# STM32F303C6T6 register map
File version: 1.0
Registers are 32-bit, access not given, reset 0x0 unless marked. A register's access mark holds for its fields unless they carry their own. Offsets are from the block's base; [hi:lo] are bit positions; {n}, {i} and the like mark numbered series; 'fields as' and 'values as' point back to an identical list.

## FLASH
Base 0x40022000
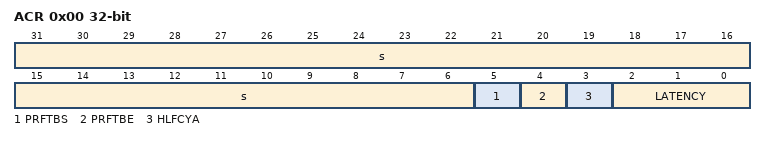
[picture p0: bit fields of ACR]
0x00 ACR
  [31:6] s, [5] PRFTBS, [4] PRFTBE, [3] HLFCYA, [2:0] LATENCY
0x04 KEYR
  [31:0] FKEYR
0x08 OPTKEYR
0x0C SR
  [5] EOP, [4] WRPRTERR, [2] PGERR, [31:1] s, [0] BSY
0x10 CR
  [13] OBL_LAUNCH, [12] EOPIE, [10] ERRIE, [9] OPTWRE, [7] LOCK, [6] STRT, [5] OPTER, [4] OPTPG, [31:3] s, [2] MER, [1] PER, [0] PG
0x14 AR
  [31:0] FAR
0x1C OBR
  [31:24] Data1, [23:16] Data0, [14] SRAM_PE, [13] VDDA_MONITOR, [12] nBOOT1, [10] nRST_STDBY, [9] nRST_STOP, [8] WDG_SW, [15:3] s, [2:1] RDPRT, [0] OPTERR
0x20 WRPR
  [31:0] WRP

## CRC
Base 0x40023000
0x00 DR
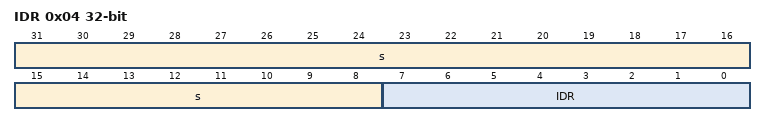
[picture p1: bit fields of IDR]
0x04 IDR
  [31:8] s, [7:0] IDR
0x08 CR
  [7] REV_OUT, [6:5] REV_IN, [4:3] POLYSIZE, [31:1] s, [0] RESET
0x10 INIT
  [31:0] CRC_INIT
0x14 POL
  [31:0] Polynomialcoefficients

## TSC
Base 0x40024000
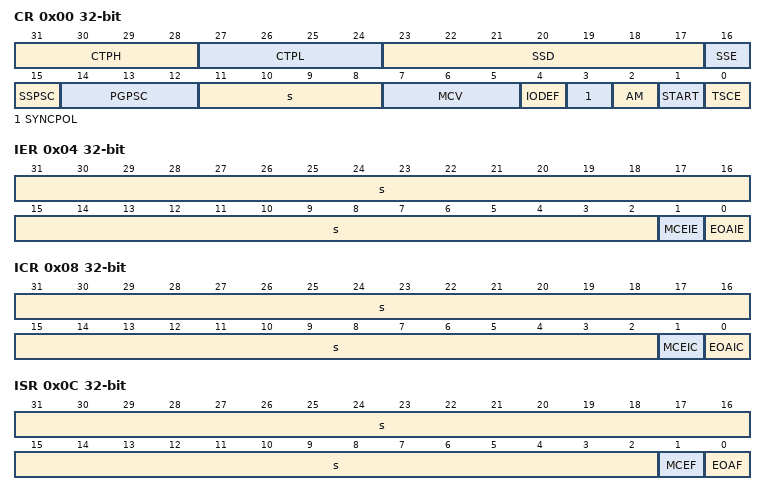
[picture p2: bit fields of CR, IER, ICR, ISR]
0x00 CR
  [31:28] CTPH, [27:24] CTPL, [23:17] SSD, [16] SSE, [15] SSPSC, [14:12] PGPSC, [11:8] s, [7:5] MCV, [4] IODEF, [3] SYNCPOL, [2] AM, [1] START, [0] TSCE
0x04 IER
  [31:2] s, [1] MCEIE, [0] EOAIE
0x08 ICR
  [31:2] s, [1] MCEIC, [0] EOAIC
0x0C ISR
  [31:2] s, [1] MCEF, [0] EOAF
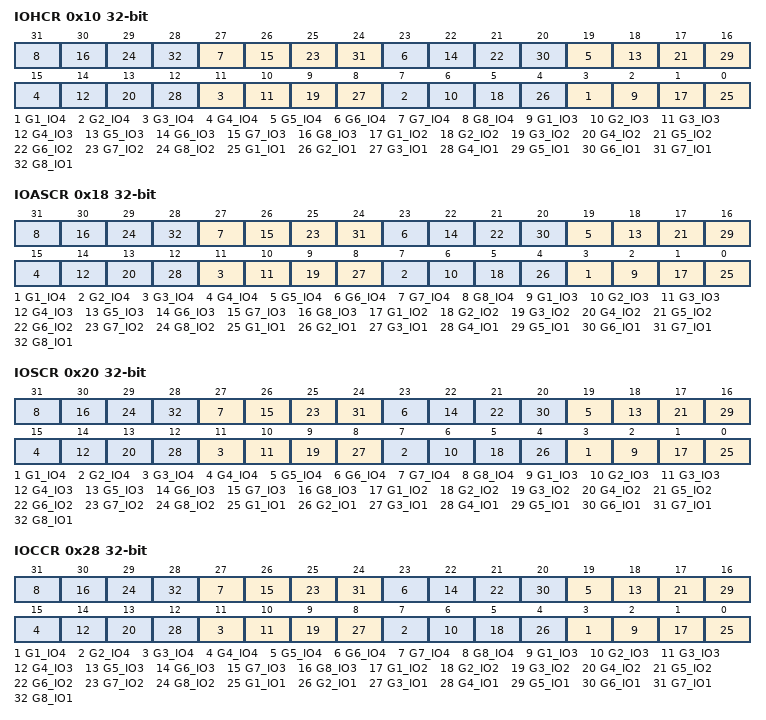
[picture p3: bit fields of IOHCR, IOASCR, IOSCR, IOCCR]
0x10 IOHCR
  [4n-1] G{n}_IO4 (n=1..8), [4n-2] G{n}_IO3 (n=1..8), [4n-3] G{n}_IO2 (n=1..8), [4n-4] G{n}_IO1 (n=1..8)
0x18 IOASCR
  fields as IOHCR
0x20 IOSCR
  fields as IOHCR
0x28 IOCCR
  fields as IOHCR
0x30 IOGCSR
  [n+15] G{n}S (n=1..8), [31:8] s, [n-1] G{n}E (n=1..8)
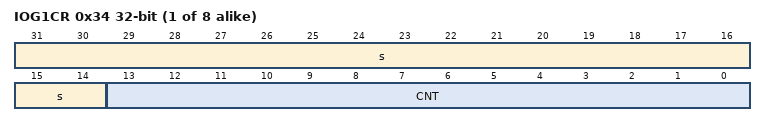
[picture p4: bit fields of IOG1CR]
{0x30+4i} IOG{i}CR (i=1..8)
  [31:14] s, [13:0] CNT

## GPIOA
Base 0x48000000
Same registers: GPIOB 0x48000400, GPIOC 0x48000800, GPIOD 0x48000C00, GPIOF 0x48001400
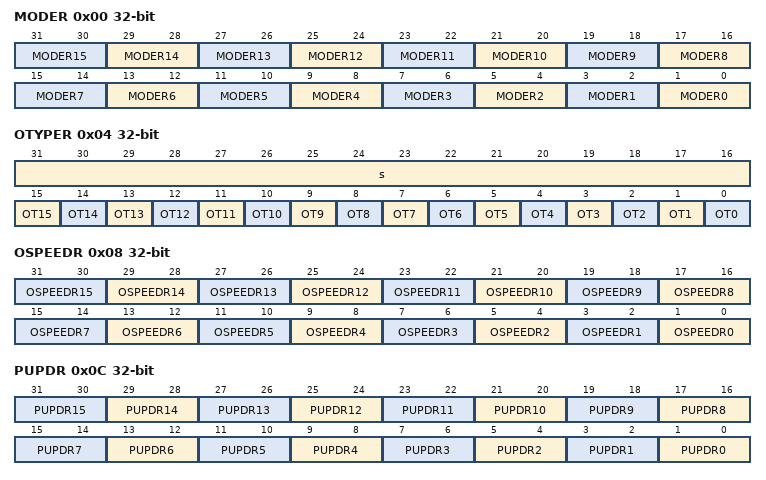
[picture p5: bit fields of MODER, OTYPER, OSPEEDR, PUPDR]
0x00 MODER
  [2n+1:2n] MODER{n} (n=0..15)
0x04 OTYPER
  [31:16] s, [n] OT{n} (n=0..15)
0x08 OSPEEDR
  [2n+1:2n] OSPEEDR{n} (n=0..15)
0x0C PUPDR
  [2n+1:2n] PUPDR{n} (n=0..15)
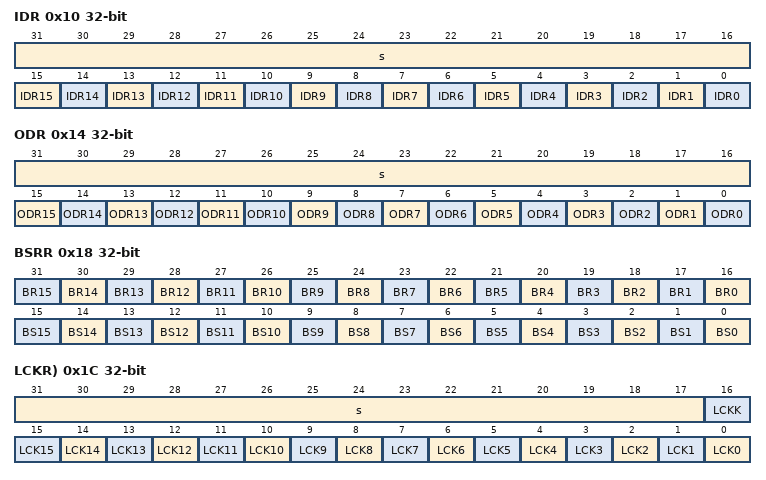
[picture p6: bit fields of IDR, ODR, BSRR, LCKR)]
0x10 IDR
  [31:16] s, [n] IDR{n} (n=0..15)
0x14 ODR
  [31:16] s, [n] ODR{n} (n=0..15)
0x18 BSRR
  [n+16] BR{n} (n=0..15), [n] BS{n} (n=0..15)
0x1C LCKR)
  [31:17] s, [16] LCKK, [n] LCK{n} (n=0..15)
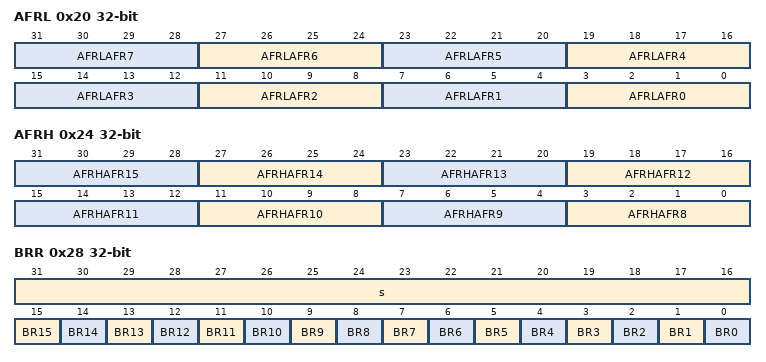
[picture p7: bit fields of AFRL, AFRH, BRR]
0x20 AFRL
  [4n+3:4n] AFRLAFR{n} (n=0..7)
0x24 AFRH
  [4n-29:4n-32] AFRHAFR{n} (n=8..15)
0x28 BRR
  [31:16] s, [n] BR{n} (n=0..15)

## ADC1
Base 0x50000000
Same registers: ADC2 0x50000100
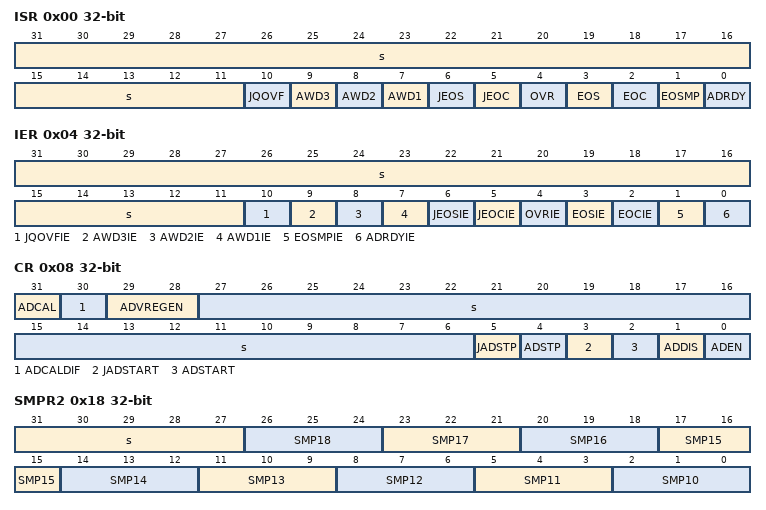
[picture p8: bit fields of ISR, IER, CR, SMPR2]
0x00 ISR
  [31:11] s, [10] JQOVF, [9] AWD3, [8] AWD2, [7] AWD1, [6] JEOS, [5] JEOC, [4] OVR, [3] EOS, [2] EOC, [1] EOSMP, [0] ADRDY
0x04 IER
  [31:11] s, [10] JQOVFIE, [9] AWD3IE, [8] AWD2IE, [7] AWD1IE, [6] JEOSIE, [5] JEOCIE, [4] OVRIE, [3] EOSIE, [2] EOCIE, [1] EOSMPIE, [0] ADRDYIE
0x08 CR
  [31] ADCAL, [30] ADCALDIF, [29:28] ADVREGEN, [27:6] s, [5] JADSTP, [4] ADSTP, [3] JADSTART, [2] ADSTART, [1] ADDIS, [0] ADEN
0x0C CFGR
  [30:26] AWD1CH, [25] JAUTO, [24] JAWD1EN, [23] AWD1EN, [22] AWD1SGL, [21] JQM, [20] JDISCEN, [19:17] DISCNUM, [16] DISCEN, [14] AUTDLY, [13] CONT, [12] OVRMOD, [11:10] EXTEN, [9:6] EXTSEL, [5] ALIGN, [4:3] RES, [31:2] s, [1] DMACFG, [0] DMAEN
0x14 SMPR1
  [3n+2:3n] SMP{n} (n=1..9), [31:0] s
0x18 SMPR2
  [31:27] s, [3n-28:3n-30] SMP{n} (n=10..18)
0x20 TR1
  [27:16] HT1, [31:12] s, [11:0] LT1
0x24 TR2
  [23:16] HT2, [31:8] s, [7:0] LT2
0x28 TR3
  [23:16] HT3, [31:8] s, [7:0] LT3
0x30 SQR1
  [6n+4:6n] SQ{n} (n=1..4), [31:4] s, [3:0] L
0x34 SQR2
  [6n-26:6n-30] SQ{n} (n=5..9), [31:5] s
0x38 SQR3
  [6n-56:6n-60] SQ{n} (n=10..14), [31:5] s
0x3C SQR4
  [10:6] SQ16, [31:5] s, [4:0] SQ15
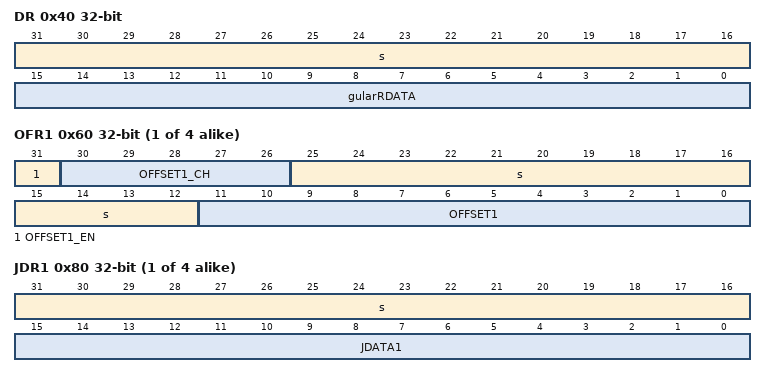
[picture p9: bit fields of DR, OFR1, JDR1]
0x40 DR
  [31:16] s, [15:0] gularRDATA
0x4C JSQR
  [6n+6:6n+2] JSQ{n} (n=1..4), [31:13] s, [7:6] JEXTEN, [5:2] JEXTSEL, [1:0] JL
{0x5C+4i} OFR{i} (i=1..4)
  [31] OFFSET{i}_EN, [30:26] OFFSET{i}_CH, [25:12] s, [11:0] OFFSET{i}
{0x7C+4i} JDR{i} (i=1..4)
  [31:16] s, [15:0] JDATA{i}
0xA0 AWD2CR
  [18:1] AWD2CH, [31:0] s
0xA4 AWD3CR
  [18:1] AWD3CH, [31:0] s
0xB0 DIFSEL
  [18:1] DIFSEL, [31:0] s
0xB4 CALFACT
  [22:16] CALFACT_D, [31:7] s, [6:0] CALFACT_S
